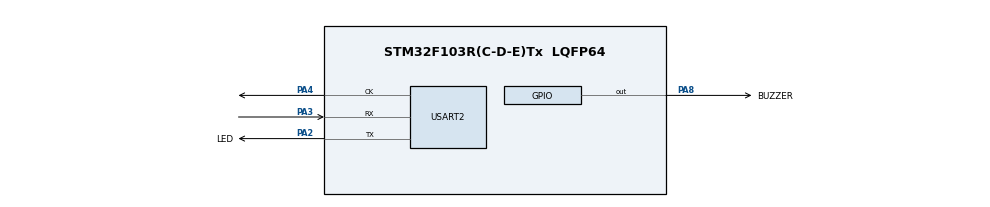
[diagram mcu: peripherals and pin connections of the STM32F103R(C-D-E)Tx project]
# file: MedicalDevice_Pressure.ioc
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Mcu.Family=STM32F1
Mcu.Name=STM32F103R(C-D-E)Tx
Mcu.Package=LQFP64
NVIC.PriorityGroup=NVIC_PRIORITYGROUP_4
NVIC.USART2_IRQn=true\:0\:0\:false\:false\:true\:true\:true\:true
PA2.GPIO_Label=LED
PA2.Mode=Synchronous
PA2.Signal=USART2_TX
PA3.Mode=Synchronous
PA3.Signal=USART2_RX
PA4.Mode=Synchronous
PA4.Signal=USART2_CK
PA8.GPIO_Label=BUZZER
PA8.Signal=GPIO_Output
PB14.Signal=SPI2_MISO
PB15.Signal=SPI2_MOSI
ProjectManager.HeapSize=0x200
ProjectManager.StackSize=0x400
ProjectManager.TargetToolchain=STM32CubeIDE
RCC.APB1Freq_Value=8000000
RCC.APB2Freq_Value=8000000
USART2.VirtualMode=VM_SYNC
board=custom

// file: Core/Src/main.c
/* USER CODE BEGIN Header */
/**
  ******************************************************************************
  * @file           : main.c
  * @brief          : Main program body
  ******************************************************************************
  * @attention
  *
  * Copyright (c) 2023 STMicroelectronics.
  * All rights reserved.
  *
  * This software is licensed under terms that can be found in the LICENSE file
  * in the root directory of this software component.
  * If no LICENSE file comes with this software, it is provided AS-IS.
  *
  ******************************************************************************
  */
/* USER CODE END Header */
#include "main.h"

USART_HandleTypeDef husart2;

void SystemClock_Config(void);
static void MX_GPIO_Init(void);
static void MX_USART2_Init(void);

int main(void)
{

  /* MCU Configuration--------------------------------------------------------*/

  /* Reset of all peripherals, Initializes the Flash interface and the Systick. */
  HAL_Init();

  /* Configure the system clock */
  SystemClock_Config();

  /* Initialize all configured peripherals */
  MX_GPIO_Init();
  MX_USART2_Init();

  /* Infinite loop */
  while (1)
  {

    /* USER CODE BEGIN 3 */
	  //HAL_GPIO_WritePin(LED_GPIO_Port, LED_Pin, GPIO_PIN_SET);
	  //HAL_GPIO_WritePin(BUZZER_GPIO_Port, BUZZER_Pin, GPIO_PIN_SET);
	  //HAL_Delay(2000);
	  //HAL_GPIO_WritePin(LED_GPIO_Port, LED_Pin, GPIO_PIN_RESET);
	  //HAL_GPIO_WritePin(BUZZER_GPIO_Port, BUZZER_Pin, GPIO_PIN_RESET);
	  HAL_GPIO_TogglePin(LED_GPIO_Port, LED_Pin);
	  HAL_Delay(1000);
  }
  /* USER CODE END 3 */
}

void SystemClock_Config(void)
{
  RCC_OscInitTypeDef RCC_OscInitStruct = {0};
  RCC_ClkInitTypeDef RCC_ClkInitStruct = {0};

  /** Initializes the RCC Oscillators according to the specified parameters
  * in the RCC_OscInitTypeDef structure.
  */
  RCC_OscInitStruct.OscillatorType = RCC_OSCILLATORTYPE_HSI;
  RCC_OscInitStruct.HSIState = RCC_HSI_ON;
  RCC_OscInitStruct.HSICalibrationValue = RCC_HSICALIBRATION_DEFAULT;
  RCC_OscInitStruct.PLL.PLLState = RCC_PLL_NONE;
  if (HAL_RCC_OscConfig(&RCC_OscInitStruct) != HAL_OK)
  {
    Error_Handler();
  }

  /** Initializes the CPU, AHB and APB buses clocks
  */
  RCC_ClkInitStruct.ClockType = RCC_CLOCKTYPE_HCLK|RCC_CLOCKTYPE_SYSCLK
                              |RCC_CLOCKTYPE_PCLK1|RCC_CLOCKTYPE_PCLK2;
  RCC_ClkInitStruct.SYSCLKSource = RCC_SYSCLKSOURCE_HSI;
  RCC_ClkInitStruct.AHBCLKDivider = RCC_SYSCLK_DIV1;
  RCC_ClkInitStruct.APB1CLKDivider = RCC_HCLK_DIV1;
  RCC_ClkInitStruct.APB2CLKDivider = RCC_HCLK_DIV1;

  if (HAL_RCC_ClockConfig(&RCC_ClkInitStruct, FLASH_LATENCY_0) != HAL_OK)
  {
    Error_Handler();
  }
}

static void MX_USART2_Init(void)
{

  husart2.Instance = USART2;
  husart2.Init.BaudRate = 115200;
  husart2.Init.WordLength = USART_WORDLENGTH_8B;
  husart2.Init.StopBits = USART_STOPBITS_1;
  husart2.Init.Parity = USART_PARITY_NONE;
  husart2.Init.Mode = USART_MODE_TX_RX;
  husart2.Init.CLKPolarity = USART_POLARITY_LOW;
  husart2.Init.CLKPhase = USART_PHASE_1EDGE;
  husart2.Init.CLKLastBit = USART_LASTBIT_DISABLE;
  if (HAL_USART_Init(&husart2) != HAL_OK)
  {
    Error_Handler();
  }

}

static void MX_GPIO_Init(void)
{
  GPIO_InitTypeDef GPIO_InitStruct = {0};

  /* GPIO Ports Clock Enable */
  __HAL_RCC_GPIOA_CLK_ENABLE();
  __HAL_RCC_GPIOB_CLK_ENABLE();

  /*Configure GPIO pin Output Level */
  HAL_GPIO_WritePin(BUZZER_GPIO_Port, BUZZER_Pin, GPIO_PIN_RESET);

  /*Configure GPIO pins : PB14 PB15 */
  GPIO_InitStruct.Pin = GPIO_PIN_14|GPIO_PIN_15;
  GPIO_InitStruct.Mode = GPIO_MODE_AF_PP;
  GPIO_InitStruct.Speed = GPIO_SPEED_FREQ_HIGH;
  HAL_GPIO_Init(GPIOB, &GPIO_InitStruct);

  /*Configure GPIO pin : BUZZER_Pin */
  GPIO_InitStruct.Pin = BUZZER_Pin;
  GPIO_InitStruct.Mode = GPIO_MODE_OUTPUT_PP;
  GPIO_InitStruct.Pull = GPIO_NOPULL;
  GPIO_InitStruct.Speed = GPIO_SPEED_FREQ_LOW;
  HAL_GPIO_Init(BUZZER_GPIO_Port, &GPIO_InitStruct);

}

void Error_Handler(void)
{
  __disable_irq();
  while (1)
  {
  }
}
